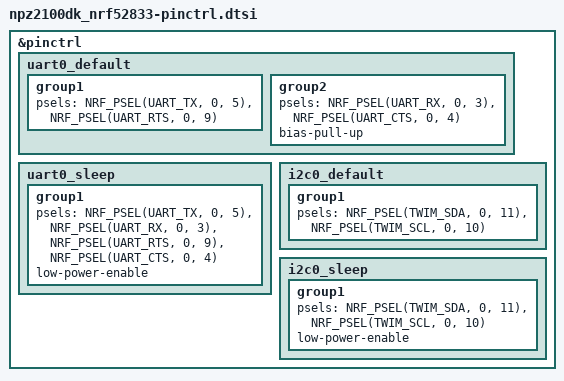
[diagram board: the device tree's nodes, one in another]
/*
 * Copyright (c) Nanopower Semiconductor AS
 * SPDX-License-Identifier: Apache-2.0
 *
 * Pin assignments from SCHEMATIC_NPZ2100-DK_1V0, sheet "BLE nRF52833".
 *
 * Note: the UART_*_ISO net names on the schematic are from the FT231X
 * side, so they are crossed relative to the nRF52833:
 *   UART_TX_ISO  (FT231X TXD)  -> P0.03 = nRF RX
 *   UART_RX_ISO  (FT231X RXD)  <- P0.05 = nRF TX
 *   UART_RTS_ISO (FT231X RTS#) -> P0.04 = nRF CTS
 *   UART_CTS_ISO (FT231X CTS#) <- P0.09 = nRF RTS
 */

&pinctrl {
	uart0_default: uart0_default {
		group1 {
			psels = <NRF_PSEL(UART_TX, 0, 5)>,
				<NRF_PSEL(UART_RTS, 0, 9)>;
		};
		group2 {
			psels = <NRF_PSEL(UART_RX, 0, 3)>,
				<NRF_PSEL(UART_CTS, 0, 4)>;
			bias-pull-up;
		};
	};

	uart0_sleep: uart0_sleep {
		group1 {
			psels = <NRF_PSEL(UART_TX, 0, 5)>,
				<NRF_PSEL(UART_RX, 0, 3)>,
				<NRF_PSEL(UART_RTS, 0, 9)>,
				<NRF_PSEL(UART_CTS, 0, 4)>;
			low-power-enable;
		};
	};

	/* I2C bus shared by the nPZ2100 (0x3C) and AS6214 (0x48, via J12/J13).
	 * External 2.2k pull-ups to VDD_HP are fitted with jumper J14.
	 */
	i2c0_default: i2c0_default {
		group1 {
			psels = <NRF_PSEL(TWIM_SDA, 0, 11)>,
				<NRF_PSEL(TWIM_SCL, 0, 10)>;
		};
	};

	i2c0_sleep: i2c0_sleep {
		group1 {
			psels = <NRF_PSEL(TWIM_SDA, 0, 11)>,
				<NRF_PSEL(TWIM_SCL, 0, 10)>;
			low-power-enable;
		};
	};
};
